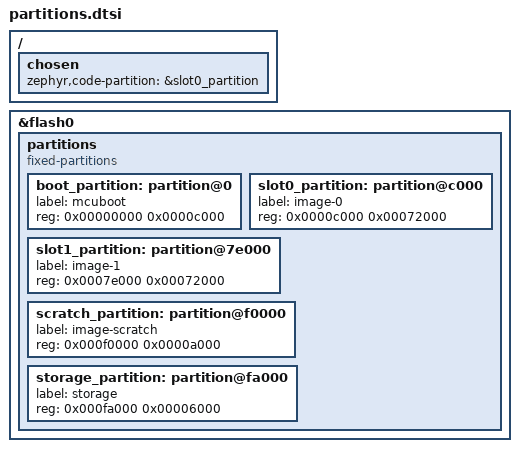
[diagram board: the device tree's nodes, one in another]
/*
 * Copyright (c) 2024 The ZMK Contributors
 *
 * SPDX-License-Identifier: MIT
 */

/delete-node/ &sd_partition;
/delete-node/ &code_partition;
/delete-node/ &storage_partition;
/delete-node/ &boot_partition;

&flash0 {
    partitions {
        compatible = "fixed-partitions";
        #address-cells = <1>;
        #size-cells = <1>;

        boot_partition: partition@0 {
            label = "mcuboot";
            reg = <0x00000000 0x0000c000>;
        };
        slot0_partition: partition@c000 {
            label = "image-0";
            reg = <0x0000c000 0x00072000>;
        };
        slot1_partition: partition@7e000 {
            label = "image-1";
            reg = <0x0007e000 0x00072000>;
        };
        scratch_partition: partition@f0000 {
            label = "image-scratch";
            reg = <0x000f0000 0x0000a000>;
        };
        storage_partition: partition@fa000 {
            label = "storage";
            reg = <0x000fa000 0x00006000>;
        };
    };
};

/ {
    chosen {
        zephyr,code-partition = &slot0_partition;
    };
};
